# iorx62n register map
Registers are 8-bit, access not given, no defined reset value unless marked. A register's access mark holds for its fields unless they carry their own. Addresses are absolute; registers are grouped by the start of their names; [hi:lo] are bit positions; {n}, {i} and the like mark numbered series; 'fields as' and 'values as' point back to an identical list.

## SFR (part 3 of 3)
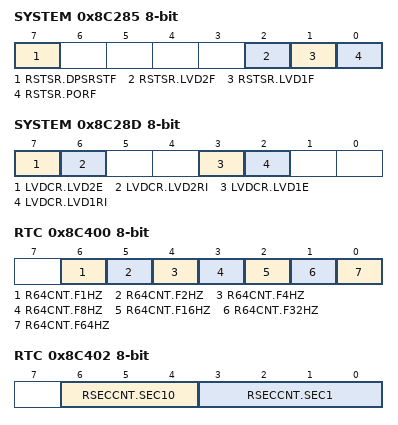
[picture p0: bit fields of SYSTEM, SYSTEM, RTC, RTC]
0x8C285 SYSTEM
  [7] RSTSR.DPSRSTF, [2] RSTSR.LVD2F, [1] RSTSR.LVD1F, [0] RSTSR.PORF
0x8C289 FLASH
  [1:0] FWEPROR.FLWE
0x8C28A SYSTEM
  [0] SUBOSCCR.SUBSTOP
0x8C28D SYSTEM
  [7] LVDCR.LVD2E, [6] LVDCR.LVD2RI, [3] LVDCR.LVD1E, [2] LVDCR.LVD1RI
0x8C400 RTC
  [6] R64CNT.F1HZ, [5] R64CNT.F2HZ, [4] R64CNT.F4HZ, [3] R64CNT.F8HZ, [2] R64CNT.F16HZ, [1] R64CNT.F32HZ, [0] R64CNT.F64HZ
0x8C402 RTC
  [6:4] RSECCNT.SEC10, [3:0] RSECCNT.SEC1
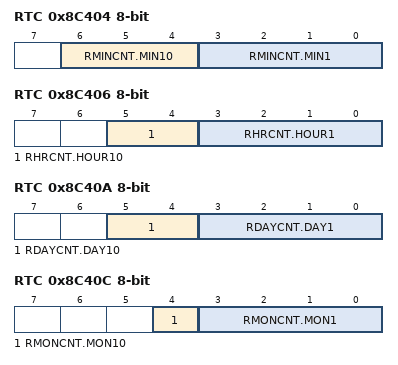
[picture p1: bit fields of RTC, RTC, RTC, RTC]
0x8C404 RTC
  [6:4] RMINCNT.MIN10, [3:0] RMINCNT.MIN1
0x8C406 RTC
  [5:4] RHRCNT.HOUR10, [3:0] RHRCNT.HOUR1
0x8C408 RTC
  [2:0] RWKCNT.DAY
0x8C40A RTC
  [5:4] RDAYCNT.DAY10, [3:0] RDAYCNT.DAY1
0x8C40C RTC
  [4] RMONCNT.MON10, [3:0] RMONCNT.MON1
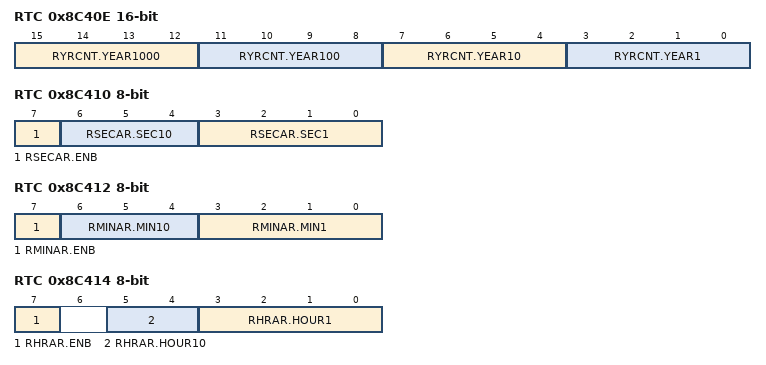
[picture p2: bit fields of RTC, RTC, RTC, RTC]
0x8C40E RTC 16-bit
  [15:12] RYRCNT.YEAR1000, [11:8] RYRCNT.YEAR100, [7:4] RYRCNT.YEAR10, [3:0] RYRCNT.YEAR1
0x8C410 RTC
  [7] RSECAR.ENB, [6:4] RSECAR.SEC10, [3:0] RSECAR.SEC1
0x8C412 RTC
  [7] RMINAR.ENB, [6:4] RMINAR.MIN10, [3:0] RMINAR.MIN1
0x8C414 RTC
  [7] RHRAR.ENB, [5:4] RHRAR.HOUR10, [3:0] RHRAR.HOUR1
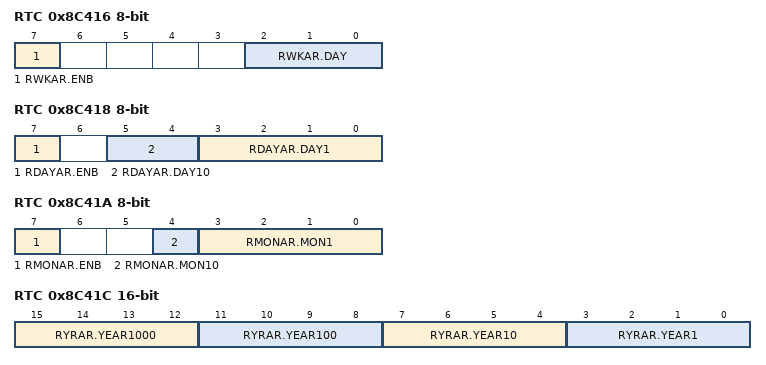
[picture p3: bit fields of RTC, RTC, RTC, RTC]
0x8C416 RTC
  [7] RWKAR.ENB, [2:0] RWKAR.DAY
0x8C418 RTC
  [7] RDAYAR.ENB, [5:4] RDAYAR.DAY10, [3:0] RDAYAR.DAY1
0x8C41A RTC
  [7] RMONAR.ENB, [4] RMONAR.MON10, [3:0] RMONAR.MON1
0x8C41C RTC 16-bit
  [15:12] RYRAR.YEAR1000, [11:8] RYRAR.YEAR100, [7:4] RYRAR.YEAR10, [3:0] RYRAR.YEAR1
0x8C41E RTC
  [7] RYRAREN.ENB
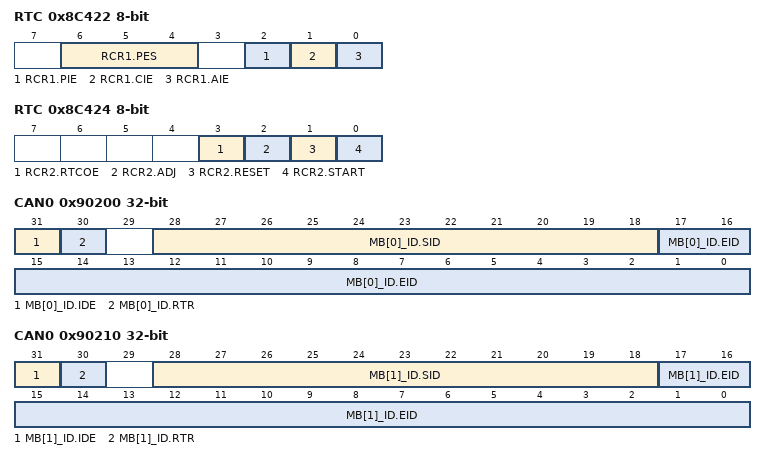
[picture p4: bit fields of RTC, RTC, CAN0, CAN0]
0x8C422 RTC
  [6:4] RCR1.PES, [2] RCR1.PIE, [1] RCR1.CIE, [0] RCR1.AIE
0x8C424 RTC
  [3] RCR2.RTCOE, [2] RCR2.ADJ, [1] RCR2.RESET, [0] RCR2.START
0x90200 CAN0 32-bit
  [31] MB[0]_ID.IDE, [30] MB[0]_ID.RTR, [28:18] MB[0]_ID.SID, [17:0] MB[0]_ID.EID
0x90204 CAN0 16-bit
  [3:0] MB[0]_DLC.DLC
0x90210 CAN0 32-bit
  [31] MB[1]_ID.IDE, [30] MB[1]_ID.RTR, [28:18] MB[1]_ID.SID, [17:0] MB[1]_ID.EID
0x90214 CAN0 16-bit
  [3:0] MB[1]_DLC.DLC
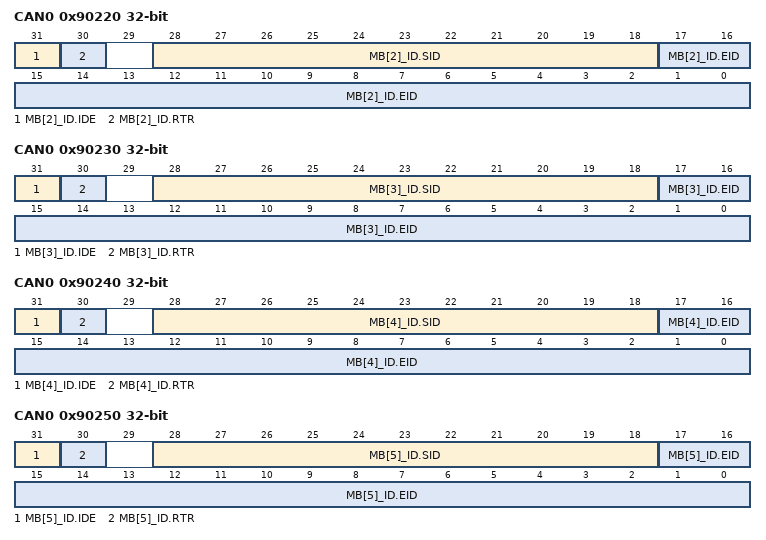
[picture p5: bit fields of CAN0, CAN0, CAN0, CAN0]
0x90220 CAN0 32-bit
  [31] MB[2]_ID.IDE, [30] MB[2]_ID.RTR, [28:18] MB[2]_ID.SID, [17:0] MB[2]_ID.EID
0x90224 CAN0 16-bit
  [3:0] MB[2]_DLC.DLC
0x90230 CAN0 32-bit
  [31] MB[3]_ID.IDE, [30] MB[3]_ID.RTR, [28:18] MB[3]_ID.SID, [17:0] MB[3]_ID.EID
0x90234 CAN0 16-bit
  [3:0] MB[3]_DLC.DLC
0x90240 CAN0 32-bit
  [31] MB[4]_ID.IDE, [30] MB[4]_ID.RTR, [28:18] MB[4]_ID.SID, [17:0] MB[4]_ID.EID
0x90244 CAN0 16-bit
  [3:0] MB[4]_DLC.DLC
0x90250 CAN0 32-bit
  [31] MB[5]_ID.IDE, [30] MB[5]_ID.RTR, [28:18] MB[5]_ID.SID, [17:0] MB[5]_ID.EID
0x90254 CAN0 16-bit
  [3:0] MB[5]_DLC.DLC
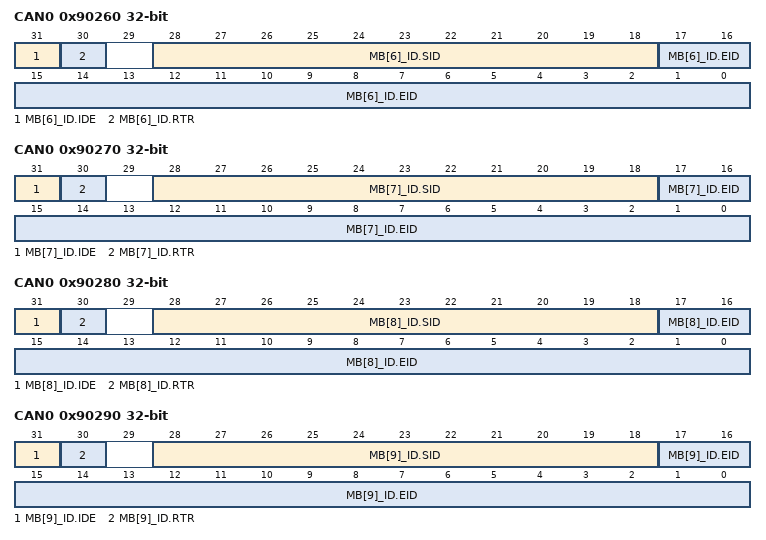
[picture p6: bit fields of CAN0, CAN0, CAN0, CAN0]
0x90260 CAN0 32-bit
  [31] MB[6]_ID.IDE, [30] MB[6]_ID.RTR, [28:18] MB[6]_ID.SID, [17:0] MB[6]_ID.EID
0x90264 CAN0 16-bit
  [3:0] MB[6]_DLC.DLC
0x90270 CAN0 32-bit
  [31] MB[7]_ID.IDE, [30] MB[7]_ID.RTR, [28:18] MB[7]_ID.SID, [17:0] MB[7]_ID.EID
0x90274 CAN0 16-bit
  [3:0] MB[7]_DLC.DLC
0x90280 CAN0 32-bit
  [31] MB[8]_ID.IDE, [30] MB[8]_ID.RTR, [28:18] MB[8]_ID.SID, [17:0] MB[8]_ID.EID
0x90284 CAN0 16-bit
  [3:0] MB[8]_DLC.DLC
0x90290 CAN0 32-bit
  [31] MB[9]_ID.IDE, [30] MB[9]_ID.RTR, [28:18] MB[9]_ID.SID, [17:0] MB[9]_ID.EID
0x90294 CAN0 16-bit
  [3:0] MB[9]_DLC.DLC
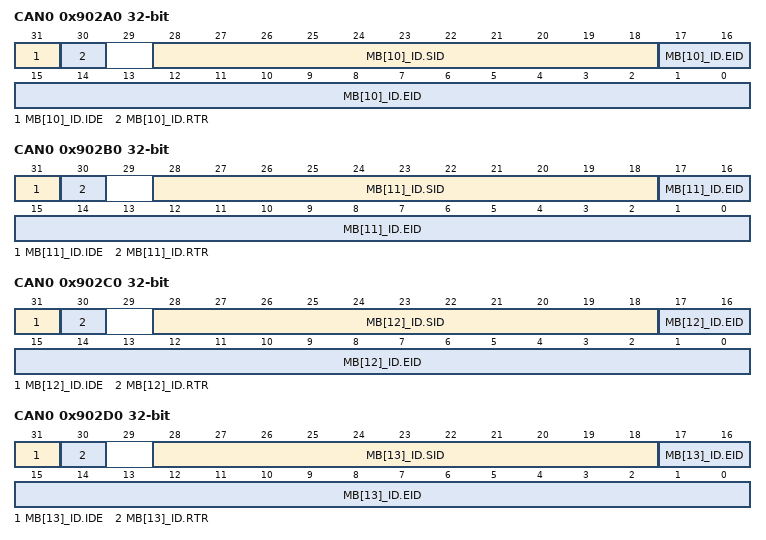
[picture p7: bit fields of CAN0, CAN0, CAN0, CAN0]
0x902A0 CAN0 32-bit
  [31] MB[10]_ID.IDE, [30] MB[10]_ID.RTR, [28:18] MB[10]_ID.SID, [17:0] MB[10]_ID.EID
0x902A4 CAN0 16-bit
  [3:0] MB[10]_DLC.DLC
0x902B0 CAN0 32-bit
  [31] MB[11]_ID.IDE, [30] MB[11]_ID.RTR, [28:18] MB[11]_ID.SID, [17:0] MB[11]_ID.EID
0x902B4 CAN0 16-bit
  [3:0] MB[11]_DLC.DLC
0x902C0 CAN0 32-bit
  [31] MB[12]_ID.IDE, [30] MB[12]_ID.RTR, [28:18] MB[12]_ID.SID, [17:0] MB[12]_ID.EID
0x902C4 CAN0 16-bit
  [3:0] MB[12]_DLC.DLC
0x902D0 CAN0 32-bit
  [31] MB[13]_ID.IDE, [30] MB[13]_ID.RTR, [28:18] MB[13]_ID.SID, [17:0] MB[13]_ID.EID
0x902D4 CAN0 16-bit
  [3:0] MB[13]_DLC.DLC
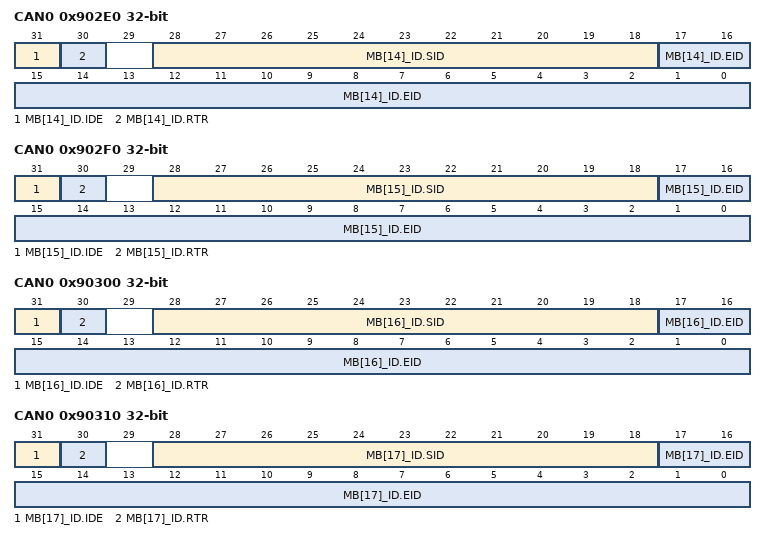
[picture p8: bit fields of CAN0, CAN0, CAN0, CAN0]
0x902E0 CAN0 32-bit
  [31] MB[14]_ID.IDE, [30] MB[14]_ID.RTR, [28:18] MB[14]_ID.SID, [17:0] MB[14]_ID.EID
0x902E4 CAN0 16-bit
  [3:0] MB[14]_DLC.DLC
0x902F0 CAN0 32-bit
  [31] MB[15]_ID.IDE, [30] MB[15]_ID.RTR, [28:18] MB[15]_ID.SID, [17:0] MB[15]_ID.EID
0x902F4 CAN0 16-bit
  [3:0] MB[15]_DLC.DLC
0x90300 CAN0 32-bit
  [31] MB[16]_ID.IDE, [30] MB[16]_ID.RTR, [28:18] MB[16]_ID.SID, [17:0] MB[16]_ID.EID
0x90304 CAN0 16-bit
  [3:0] MB[16]_DLC.DLC
0x90310 CAN0 32-bit
  [31] MB[17]_ID.IDE, [30] MB[17]_ID.RTR, [28:18] MB[17]_ID.SID, [17:0] MB[17]_ID.EID
0x90314 CAN0 16-bit
  [3:0] MB[17]_DLC.DLC
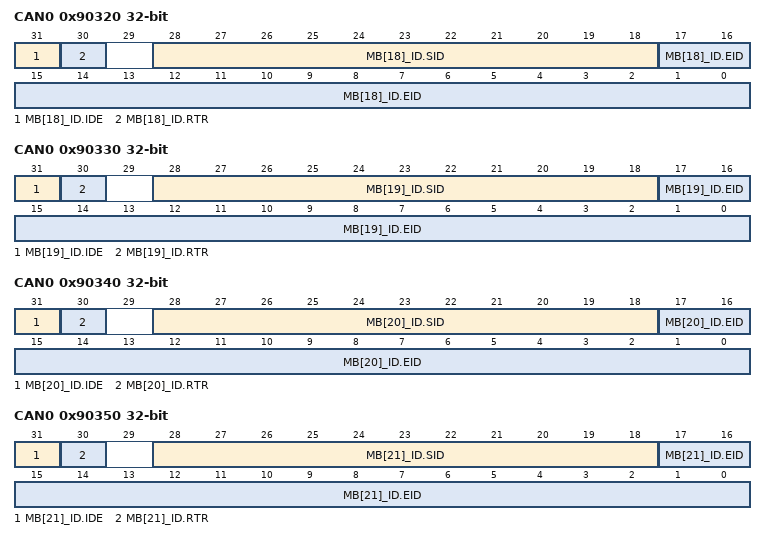
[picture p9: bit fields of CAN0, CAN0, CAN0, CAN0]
0x90320 CAN0 32-bit
  [31] MB[18]_ID.IDE, [30] MB[18]_ID.RTR, [28:18] MB[18]_ID.SID, [17:0] MB[18]_ID.EID
0x90324 CAN0 16-bit
  [3:0] MB[18]_DLC.DLC
0x90330 CAN0 32-bit
  [31] MB[19]_ID.IDE, [30] MB[19]_ID.RTR, [28:18] MB[19]_ID.SID, [17:0] MB[19]_ID.EID
0x90334 CAN0 16-bit
  [3:0] MB[19]_DLC.DLC
0x90340 CAN0 32-bit
  [31] MB[20]_ID.IDE, [30] MB[20]_ID.RTR, [28:18] MB[20]_ID.SID, [17:0] MB[20]_ID.EID
0x90344 CAN0 16-bit
  [3:0] MB[20]_DLC.DLC
0x90350 CAN0 32-bit
  [31] MB[21]_ID.IDE, [30] MB[21]_ID.RTR, [28:18] MB[21]_ID.SID, [17:0] MB[21]_ID.EID
0x90354 CAN0 16-bit
  [3:0] MB[21]_DLC.DLC
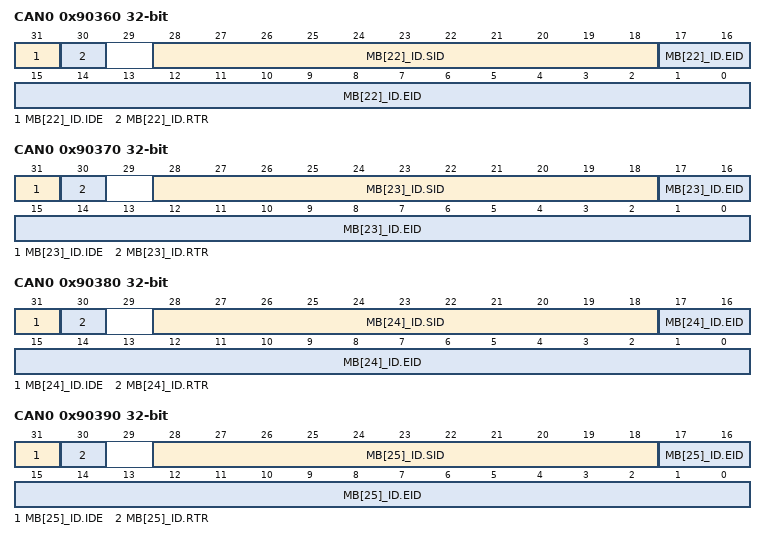
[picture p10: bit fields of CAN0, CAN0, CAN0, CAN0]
0x90360 CAN0 32-bit
  [31] MB[22]_ID.IDE, [30] MB[22]_ID.RTR, [28:18] MB[22]_ID.SID, [17:0] MB[22]_ID.EID
0x90364 CAN0 16-bit
  [3:0] MB[22]_DLC.DLC
0x90370 CAN0 32-bit
  [31] MB[23]_ID.IDE, [30] MB[23]_ID.RTR, [28:18] MB[23]_ID.SID, [17:0] MB[23]_ID.EID
0x90374 CAN0 16-bit
  [3:0] MB[23]_DLC.DLC
0x90380 CAN0 32-bit
  [31] MB[24]_ID.IDE, [30] MB[24]_ID.RTR, [28:18] MB[24]_ID.SID, [17:0] MB[24]_ID.EID
0x90384 CAN0 16-bit
  [3:0] MB[24]_DLC.DLC
0x90390 CAN0 32-bit
  [31] MB[25]_ID.IDE, [30] MB[25]_ID.RTR, [28:18] MB[25]_ID.SID, [17:0] MB[25]_ID.EID
0x90394 CAN0 16-bit
  [3:0] MB[25]_DLC.DLC
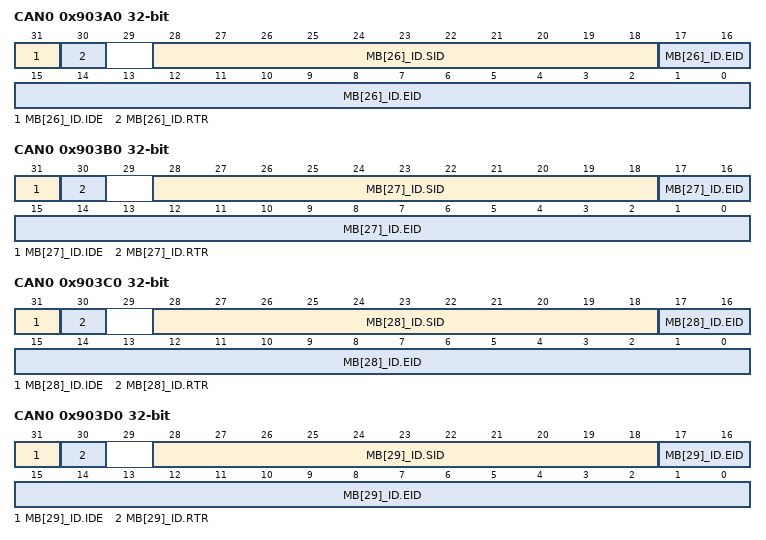
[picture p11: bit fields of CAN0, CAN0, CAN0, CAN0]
0x903A0 CAN0 32-bit
  [31] MB[26]_ID.IDE, [30] MB[26]_ID.RTR, [28:18] MB[26]_ID.SID, [17:0] MB[26]_ID.EID
0x903A4 CAN0 16-bit
  [3:0] MB[26]_DLC.DLC
0x903B0 CAN0 32-bit
  [31] MB[27]_ID.IDE, [30] MB[27]_ID.RTR, [28:18] MB[27]_ID.SID, [17:0] MB[27]_ID.EID
0x903B4 CAN0 16-bit
  [3:0] MB[27]_DLC.DLC
0x903C0 CAN0 32-bit
  [31] MB[28]_ID.IDE, [30] MB[28]_ID.RTR, [28:18] MB[28]_ID.SID, [17:0] MB[28]_ID.EID
0x903C4 CAN0 16-bit
  [3:0] MB[28]_DLC.DLC
0x903D0 CAN0 32-bit
  [31] MB[29]_ID.IDE, [30] MB[29]_ID.RTR, [28:18] MB[29]_ID.SID, [17:0] MB[29]_ID.EID
0x903D4 CAN0 16-bit
  [3:0] MB[29]_DLC.DLC
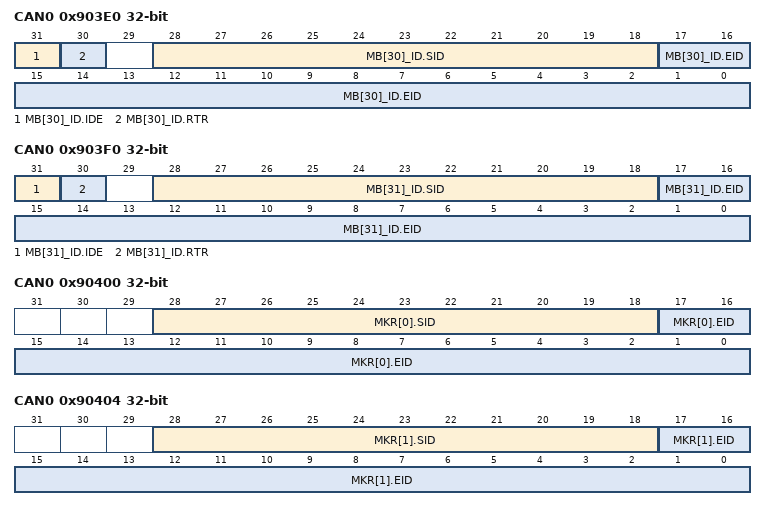
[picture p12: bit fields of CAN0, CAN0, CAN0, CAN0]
0x903E0 CAN0 32-bit
  [31] MB[30]_ID.IDE, [30] MB[30]_ID.RTR, [28:18] MB[30]_ID.SID, [17:0] MB[30]_ID.EID
0x903E4 CAN0 16-bit
  [3:0] MB[30]_DLC.DLC
0x903F0 CAN0 32-bit
  [31] MB[31]_ID.IDE, [30] MB[31]_ID.RTR, [28:18] MB[31]_ID.SID, [17:0] MB[31]_ID.EID
0x903F4 CAN0 16-bit
  [3:0] MB[31]_DLC.DLC
0x90400 CAN0 32-bit
  [28:18] MKR[0].SID, [17:0] MKR[0].EID
0x90404 CAN0 32-bit
  [28:18] MKR[1].SID, [17:0] MKR[1].EID
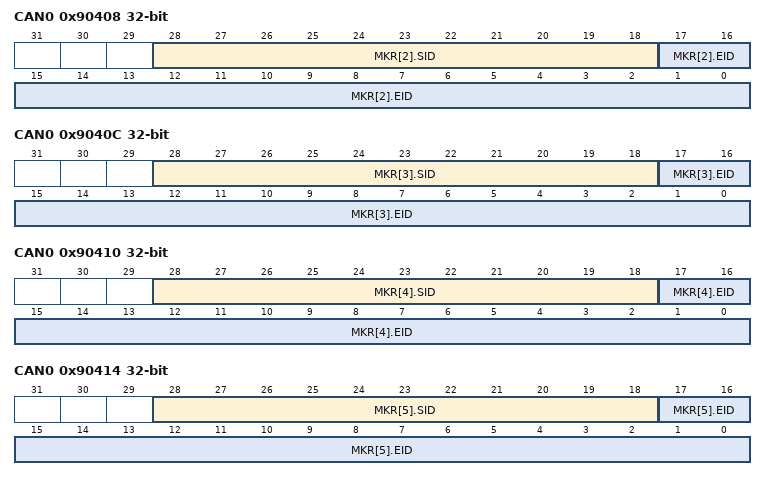
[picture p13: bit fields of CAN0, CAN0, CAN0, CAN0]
0x90408 CAN0 32-bit
  [28:18] MKR[2].SID, [17:0] MKR[2].EID
0x9040C CAN0 32-bit
  [28:18] MKR[3].SID, [17:0] MKR[3].EID
0x90410 CAN0 32-bit
  [28:18] MKR[4].SID, [17:0] MKR[4].EID
0x90414 CAN0 32-bit
  [28:18] MKR[5].SID, [17:0] MKR[5].EID
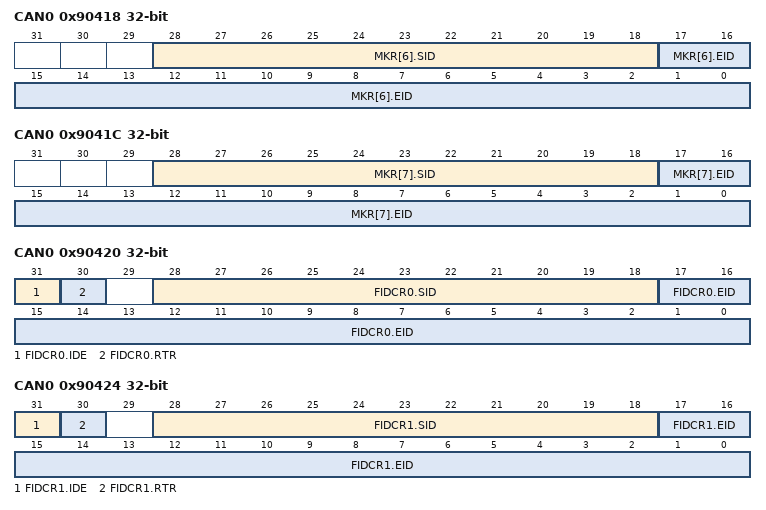
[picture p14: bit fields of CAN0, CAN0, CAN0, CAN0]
0x90418 CAN0 32-bit
  [28:18] MKR[6].SID, [17:0] MKR[6].EID
0x9041C CAN0 32-bit
  [28:18] MKR[7].SID, [17:0] MKR[7].EID
0x90420 CAN0 32-bit
  [31] FIDCR0.IDE, [30] FIDCR0.RTR, [28:18] FIDCR0.SID, [17:0] FIDCR0.EID
0x90424 CAN0 32-bit
  [31] FIDCR1.IDE, [30] FIDCR1.RTR, [28:18] FIDCR1.SID, [17:0] FIDCR1.EID
0x90820 CAN0
  [7] MCTL[0]_TX.TRMREQ, [7] MCTL[0]_RX.TRMREQ, [6] MCTL[0]_TX.RECREQ, [6] MCTL[0]_RX.RECREQ, [4] MCTL[0]_TX.ONESHOT, [4] MCTL[0]_RX.ONESHOT, [2] MCTL[0]_TX.TRMABT, [2] MCTL[0]_RX.MSGLOST, [1] MCTL[0]_TX.TRMACTIVE, [1] MCTL[0]_RX.INVALDATA, [0] MCTL[0]_TX.SENTDATA, [0] MCTL[0]_RX.NEWDATA
0x90821 CAN0
  [7] MCTL[1]_TX.TRMREQ, [7] MCTL[1]_RX.TRMREQ, [6] MCTL[1]_TX.RECREQ, [6] MCTL[1]_RX.RECREQ, [4] MCTL[1]_TX.ONESHOT, [4] MCTL[1]_RX.ONESHOT, [2] MCTL[1]_TX.TRMABT, [2] MCTL[1]_RX.MSGLOST, [1] MCTL[1]_TX.TRMACTIVE, [1] MCTL[1]_RX.INVALDATA, [0] MCTL[1]_TX.SENTDATA, [0] MCTL[1]_RX.NEWDATA
0x90822 CAN0
  [7] MCTL[2]_TX.TRMREQ, [7] MCTL[2]_RX.TRMREQ, [6] MCTL[2]_TX.RECREQ, [6] MCTL[2]_RX.RECREQ, [4] MCTL[2]_TX.ONESHOT, [4] MCTL[2]_RX.ONESHOT, [2] MCTL[2]_TX.TRMABT, [2] MCTL[2]_RX.MSGLOST, [1] MCTL[2]_TX.TRMACTIVE, [1] MCTL[2]_RX.INVALDATA, [0] MCTL[2]_TX.SENTDATA, [0] MCTL[2]_RX.NEWDATA
0x90823 CAN0
  [7] MCTL[3]_TX.TRMREQ, [7] MCTL[3]_RX.TRMREQ, [6] MCTL[3]_TX.RECREQ, [6] MCTL[3]_RX.RECREQ, [4] MCTL[3]_TX.ONESHOT, [4] MCTL[3]_RX.ONESHOT, [2] MCTL[3]_TX.TRMABT, [2] MCTL[3]_RX.MSGLOST, [1] MCTL[3]_TX.TRMACTIVE, [1] MCTL[3]_RX.INVALDATA, [0] MCTL[3]_TX.SENTDATA, [0] MCTL[3]_RX.NEWDATA
0x90824 CAN0
  [7] MCTL[4]_TX.TRMREQ, [7] MCTL[4]_RX.TRMREQ, [6] MCTL[4]_TX.RECREQ, [6] MCTL[4]_RX.RECREQ, [4] MCTL[4]_TX.ONESHOT, [4] MCTL[4]_RX.ONESHOT, [2] MCTL[4]_TX.TRMABT, [2] MCTL[4]_RX.MSGLOST, [1] MCTL[4]_TX.TRMACTIVE, [1] MCTL[4]_RX.INVALDATA, [0] MCTL[4]_TX.SENTDATA, [0] MCTL[4]_RX.NEWDATA
0x90825 CAN0
  [7] MCTL[5]_TX.TRMREQ, [7] MCTL[5]_RX.TRMREQ, [6] MCTL[5]_TX.RECREQ, [6] MCTL[5]_RX.RECREQ, [4] MCTL[5]_TX.ONESHOT, [4] MCTL[5]_RX.ONESHOT, [2] MCTL[5]_TX.TRMABT, [2] MCTL[5]_RX.MSGLOST, [1] MCTL[5]_TX.TRMACTIVE, [1] MCTL[5]_RX.INVALDATA, [0] MCTL[5]_TX.SENTDATA, [0] MCTL[5]_RX.NEWDATA
0x90826 CAN0
  [7] MCTL[6]_TX.TRMREQ, [7] MCTL[6]_RX.TRMREQ, [6] MCTL[6]_TX.RECREQ, [6] MCTL[6]_RX.RECREQ, [4] MCTL[6]_TX.ONESHOT, [4] MCTL[6]_RX.ONESHOT, [2] MCTL[6]_TX.TRMABT, [2] MCTL[6]_RX.MSGLOST, [1] MCTL[6]_TX.TRMACTIVE, [1] MCTL[6]_RX.INVALDATA, [0] MCTL[6]_TX.SENTDATA, [0] MCTL[6]_RX.NEWDATA
0x90827 CAN0
  [7] MCTL[7]_TX.TRMREQ, [7] MCTL[7]_RX.TRMREQ, [6] MCTL[7]_TX.RECREQ, [6] MCTL[7]_RX.RECREQ, [4] MCTL[7]_TX.ONESHOT, [4] MCTL[7]_RX.ONESHOT, [2] MCTL[7]_TX.TRMABT, [2] MCTL[7]_RX.MSGLOST, [1] MCTL[7]_TX.TRMACTIVE, [1] MCTL[7]_RX.INVALDATA, [0] MCTL[7]_TX.SENTDATA, [0] MCTL[7]_RX.NEWDATA
0x90828 CAN0
  [7] MCTL[8]_TX.TRMREQ, [7] MCTL[8]_RX.TRMREQ, [6] MCTL[8]_TX.RECREQ, [6] MCTL[8]_RX.RECREQ, [4] MCTL[8]_TX.ONESHOT, [4] MCTL[8]_RX.ONESHOT, [2] MCTL[8]_TX.TRMABT, [2] MCTL[8]_RX.MSGLOST, [1] MCTL[8]_TX.TRMACTIVE, [1] MCTL[8]_RX.INVALDATA, [0] MCTL[8]_TX.SENTDATA, [0] MCTL[8]_RX.NEWDATA
0x90829 CAN0
  [7] MCTL[9]_TX.TRMREQ, [7] MCTL[9]_RX.TRMREQ, [6] MCTL[9]_TX.RECREQ, [6] MCTL[9]_RX.RECREQ, [4] MCTL[9]_TX.ONESHOT, [4] MCTL[9]_RX.ONESHOT, [2] MCTL[9]_TX.TRMABT, [2] MCTL[9]_RX.MSGLOST, [1] MCTL[9]_TX.TRMACTIVE, [1] MCTL[9]_RX.INVALDATA, [0] MCTL[9]_TX.SENTDATA, [0] MCTL[9]_RX.NEWDATA
0x9082A CAN0
  [7] MCTL[10]_TX.TRMREQ, [7] MCTL[10]_RX.TRMREQ, [6] MCTL[10]_TX.RECREQ, [6] MCTL[10]_RX.RECREQ, [4] MCTL[10]_TX.ONESHOT, [4] MCTL[10]_RX.ONESHOT, [2] MCTL[10]_TX.TRMABT, [2] MCTL[10]_RX.MSGLOST, [1] MCTL[10]_TX.TRMACTIVE, [1] MCTL[10]_RX.INVALDATA, [0] MCTL[10]_TX.SENTDATA, [0] MCTL[10]_RX.NEWDATA
0x9082B CAN0
  [7] MCTL[11]_TX.TRMREQ, [7] MCTL[11]_RX.TRMREQ, [6] MCTL[11]_TX.RECREQ, [6] MCTL[11]_RX.RECREQ, [4] MCTL[11]_TX.ONESHOT, [4] MCTL[11]_RX.ONESHOT, [2] MCTL[11]_TX.TRMABT, [2] MCTL[11]_RX.MSGLOST, [1] MCTL[11]_TX.TRMACTIVE, [1] MCTL[11]_RX.INVALDATA, [0] MCTL[11]_TX.SENTDATA, [0] MCTL[11]_RX.NEWDATA
0x9082C CAN0
  [7] MCTL[12]_TX.TRMREQ, [7] MCTL[12]_RX.TRMREQ, [6] MCTL[12]_TX.RECREQ, [6] MCTL[12]_RX.RECREQ, [4] MCTL[12]_TX.ONESHOT, [4] MCTL[12]_RX.ONESHOT, [2] MCTL[12]_TX.TRMABT, [2] MCTL[12]_RX.MSGLOST, [1] MCTL[12]_TX.TRMACTIVE, [1] MCTL[12]_RX.INVALDATA, [0] MCTL[12]_TX.SENTDATA, [0] MCTL[12]_RX.NEWDATA
0x9082D CAN0
  [7] MCTL[13]_TX.TRMREQ, [7] MCTL[13]_RX.TRMREQ, [6] MCTL[13]_TX.RECREQ, [6] MCTL[13]_RX.RECREQ, [4] MCTL[13]_TX.ONESHOT, [4] MCTL[13]_RX.ONESHOT, [2] MCTL[13]_TX.TRMABT, [2] MCTL[13]_RX.MSGLOST, [1] MCTL[13]_TX.TRMACTIVE, [1] MCTL[13]_RX.INVALDATA, [0] MCTL[13]_TX.SENTDATA, [0] MCTL[13]_RX.NEWDATA
0x9082E CAN0
  [7] MCTL[14]_TX.TRMREQ, [7] MCTL[14]_RX.TRMREQ, [6] MCTL[14]_TX.RECREQ, [6] MCTL[14]_RX.RECREQ, [4] MCTL[14]_TX.ONESHOT, [4] MCTL[14]_RX.ONESHOT, [2] MCTL[14]_TX.TRMABT, [2] MCTL[14]_RX.MSGLOST, [1] MCTL[14]_TX.TRMACTIVE, [1] MCTL[14]_RX.INVALDATA, [0] MCTL[14]_TX.SENTDATA, [0] MCTL[14]_RX.NEWDATA
0x9082F CAN0
  [7] MCTL[15]_TX.TRMREQ, [7] MCTL[15]_RX.TRMREQ, [6] MCTL[15]_TX.RECREQ, [6] MCTL[15]_RX.RECREQ, [4] MCTL[15]_TX.ONESHOT, [4] MCTL[15]_RX.ONESHOT, [2] MCTL[15]_TX.TRMABT, [2] MCTL[15]_RX.MSGLOST, [1] MCTL[15]_TX.TRMACTIVE, [1] MCTL[15]_RX.INVALDATA, [0] MCTL[15]_TX.SENTDATA, [0] MCTL[15]_RX.NEWDATA
0x90830 CAN0
  [7] MCTL[16]_TX.TRMREQ, [7] MCTL[16]_RX.TRMREQ, [6] MCTL[16]_TX.RECREQ, [6] MCTL[16]_RX.RECREQ, [4] MCTL[16]_TX.ONESHOT, [4] MCTL[16]_RX.ONESHOT, [2] MCTL[16]_TX.TRMABT, [2] MCTL[16]_RX.MSGLOST, [1] MCTL[16]_TX.TRMACTIVE, [1] MCTL[16]_RX.INVALDATA, [0] MCTL[16]_TX.SENTDATA, [0] MCTL[16]_RX.NEWDATA
0x90831 CAN0
  [7] MCTL[17]_TX.TRMREQ, [7] MCTL[17]_RX.TRMREQ, [6] MCTL[17]_TX.RECREQ, [6] MCTL[17]_RX.RECREQ, [4] MCTL[17]_TX.ONESHOT, [4] MCTL[17]_RX.ONESHOT, [2] MCTL[17]_TX.TRMABT, [2] MCTL[17]_RX.MSGLOST, [1] MCTL[17]_TX.TRMACTIVE, [1] MCTL[17]_RX.INVALDATA, [0] MCTL[17]_TX.SENTDATA, [0] MCTL[17]_RX.NEWDATA
0x90832 CAN0
  [7] MCTL[18]_TX.TRMREQ, [7] MCTL[18]_RX.TRMREQ, [6] MCTL[18]_TX.RECREQ, [6] MCTL[18]_RX.RECREQ, [4] MCTL[18]_TX.ONESHOT, [4] MCTL[18]_RX.ONESHOT, [2] MCTL[18]_TX.TRMABT, [2] MCTL[18]_RX.MSGLOST, [1] MCTL[18]_TX.TRMACTIVE, [1] MCTL[18]_RX.INVALDATA, [0] MCTL[18]_TX.SENTDATA, [0] MCTL[18]_RX.NEWDATA
0x90833 CAN0
  [7] MCTL[19]_TX.TRMREQ, [7] MCTL[19]_RX.TRMREQ, [6] MCTL[19]_TX.RECREQ, [6] MCTL[19]_RX.RECREQ, [4] MCTL[19]_TX.ONESHOT, [4] MCTL[19]_RX.ONESHOT, [2] MCTL[19]_TX.TRMABT, [2] MCTL[19]_RX.MSGLOST, [1] MCTL[19]_TX.TRMACTIVE, [1] MCTL[19]_RX.INVALDATA, [0] MCTL[19]_TX.SENTDATA, [0] MCTL[19]_RX.NEWDATA
0x90834 CAN0
  [7] MCTL[20]_TX.TRMREQ, [7] MCTL[20]_RX.TRMREQ, [6] MCTL[20]_TX.RECREQ, [6] MCTL[20]_RX.RECREQ, [4] MCTL[20]_TX.ONESHOT, [4] MCTL[20]_RX.ONESHOT, [2] MCTL[20]_TX.TRMABT, [2] MCTL[20]_RX.MSGLOST, [1] MCTL[20]_TX.TRMACTIVE, [1] MCTL[20]_RX.INVALDATA, [0] MCTL[20]_TX.SENTDATA, [0] MCTL[20]_RX.NEWDATA
0x90835 CAN0
  [7] MCTL[21]_TX.TRMREQ, [7] MCTL[21]_RX.TRMREQ, [6] MCTL[21]_TX.RECREQ, [6] MCTL[21]_RX.RECREQ, [4] MCTL[21]_TX.ONESHOT, [4] MCTL[21]_RX.ONESHOT, [2] MCTL[21]_TX.TRMABT, [2] MCTL[21]_RX.MSGLOST, [1] MCTL[21]_TX.TRMACTIVE, [1] MCTL[21]_RX.INVALDATA, [0] MCTL[21]_TX.SENTDATA, [0] MCTL[21]_RX.NEWDATA
0x90836 CAN0
  [7] MCTL[22]_TX.TRMREQ, [7] MCTL[22]_RX.TRMREQ, [6] MCTL[22]_TX.RECREQ, [6] MCTL[22]_RX.RECREQ, [4] MCTL[22]_TX.ONESHOT, [4] MCTL[22]_RX.ONESHOT, [2] MCTL[22]_TX.TRMABT, [2] MCTL[22]_RX.MSGLOST, [1] MCTL[22]_TX.TRMACTIVE, [1] MCTL[22]_RX.INVALDATA, [0] MCTL[22]_TX.SENTDATA, [0] MCTL[22]_RX.NEWDATA
0x90837 CAN0
  [7] MCTL[23]_TX.TRMREQ, [7] MCTL[23]_RX.TRMREQ, [6] MCTL[23]_TX.RECREQ, [6] MCTL[23]_RX.RECREQ, [4] MCTL[23]_TX.ONESHOT, [4] MCTL[23]_RX.ONESHOT, [2] MCTL[23]_TX.TRMABT, [2] MCTL[23]_RX.MSGLOST, [1] MCTL[23]_TX.TRMACTIVE, [1] MCTL[23]_RX.INVALDATA, [0] MCTL[23]_TX.SENTDATA, [0] MCTL[23]_RX.NEWDATA
0x90838 CAN0
  [7] MCTL[24]_TX.TRMREQ, [7] MCTL[24]_RX.TRMREQ, [6] MCTL[24]_TX.RECREQ, [6] MCTL[24]_RX.RECREQ, [4] MCTL[24]_TX.ONESHOT, [4] MCTL[24]_RX.ONESHOT, [2] MCTL[24]_TX.TRMABT, [2] MCTL[24]_RX.MSGLOST, [1] MCTL[24]_TX.TRMACTIVE, [1] MCTL[24]_RX.INVALDATA, [0] MCTL[24]_TX.SENTDATA, [0] MCTL[24]_RX.NEWDATA
0x90839 CAN0
  [7] MCTL[25]_TX.TRMREQ, [7] MCTL[25]_RX.TRMREQ, [6] MCTL[25]_TX.RECREQ, [6] MCTL[25]_RX.RECREQ, [4] MCTL[25]_TX.ONESHOT, [4] MCTL[25]_RX.ONESHOT, [2] MCTL[25]_TX.TRMABT, [2] MCTL[25]_RX.MSGLOST, [1] MCTL[25]_TX.TRMACTIVE, [1] MCTL[25]_RX.INVALDATA, [0] MCTL[25]_TX.SENTDATA, [0] MCTL[25]_RX.NEWDATA
0x9083A CAN0
  [7] MCTL[26]_TX.TRMREQ, [7] MCTL[26]_RX.TRMREQ, [6] MCTL[26]_TX.RECREQ, [6] MCTL[26]_RX.RECREQ, [4] MCTL[26]_TX.ONESHOT, [4] MCTL[26]_RX.ONESHOT, [2] MCTL[26]_TX.TRMABT, [2] MCTL[26]_RX.MSGLOST, [1] MCTL[26]_TX.TRMACTIVE, [1] MCTL[26]_RX.INVALDATA, [0] MCTL[26]_TX.SENTDATA, [0] MCTL[26]_RX.NEWDATA
0x9083B CAN0
  [7] MCTL[27]_TX.TRMREQ, [7] MCTL[27]_RX.TRMREQ, [6] MCTL[27]_TX.RECREQ, [6] MCTL[27]_RX.RECREQ, [4] MCTL[27]_TX.ONESHOT, [4] MCTL[27]_RX.ONESHOT, [2] MCTL[27]_TX.TRMABT, [2] MCTL[27]_RX.MSGLOST, [1] MCTL[27]_TX.TRMACTIVE, [1] MCTL[27]_RX.INVALDATA, [0] MCTL[27]_TX.SENTDATA, [0] MCTL[27]_RX.NEWDATA
0x9083C CAN0
  [7] MCTL[28]_TX.TRMREQ, [7] MCTL[28]_RX.TRMREQ, [6] MCTL[28]_TX.RECREQ, [6] MCTL[28]_RX.RECREQ, [4] MCTL[28]_TX.ONESHOT, [4] MCTL[28]_RX.ONESHOT, [2] MCTL[28]_TX.TRMABT, [2] MCTL[28]_RX.MSGLOST, [1] MCTL[28]_TX.TRMACTIVE, [1] MCTL[28]_RX.INVALDATA, [0] MCTL[28]_TX.SENTDATA, [0] MCTL[28]_RX.NEWDATA
0x9083D CAN0
  [7] MCTL[29]_TX.TRMREQ, [7] MCTL[29]_RX.TRMREQ, [6] MCTL[29]_TX.RECREQ, [6] MCTL[29]_RX.RECREQ, [4] MCTL[29]_TX.ONESHOT, [4] MCTL[29]_RX.ONESHOT, [2] MCTL[29]_TX.TRMABT, [2] MCTL[29]_RX.MSGLOST, [1] MCTL[29]_TX.TRMACTIVE, [1] MCTL[29]_RX.INVALDATA, [0] MCTL[29]_TX.SENTDATA, [0] MCTL[29]_RX.NEWDATA
0x9083E CAN0
  [7] MCTL[30]_TX.TRMREQ, [7] MCTL[30]_RX.TRMREQ, [6] MCTL[30]_TX.RECREQ, [6] MCTL[30]_RX.RECREQ, [4] MCTL[30]_TX.ONESHOT, [4] MCTL[30]_RX.ONESHOT, [2] MCTL[30]_TX.TRMABT, [2] MCTL[30]_RX.MSGLOST, [1] MCTL[30]_TX.TRMACTIVE, [1] MCTL[30]_RX.INVALDATA, [0] MCTL[30]_TX.SENTDATA, [0] MCTL[30]_RX.NEWDATA
0x9083F CAN0
  [7] MCTL[31]_TX.TRMREQ, [7] MCTL[31]_RX.TRMREQ, [6] MCTL[31]_TX.RECREQ, [6] MCTL[31]_RX.RECREQ, [4] MCTL[31]_TX.ONESHOT, [4] MCTL[31]_RX.ONESHOT, [2] MCTL[31]_TX.TRMABT, [2] MCTL[31]_RX.MSGLOST, [1] MCTL[31]_TX.TRMACTIVE, [1] MCTL[31]_RX.INVALDATA, [0] MCTL[31]_TX.SENTDATA, [0] MCTL[31]_RX.NEWDATA
0x90840 CAN0 16-bit
  [13] CTLR.RBOC, [12:11] CTLR.BOM, [10] CTLR.SLPM, [9:8] CTLR.CANM, [7:6] CTLR.TSPS, [5] CTLR.TSRC, [4] CTLR.TPM, [3] CTLR.MLM, [2:1] CTLR.IDFM, [0] CTLR.MBM
0x90842 CAN0 16-bit
  [14] STR.RECST, [13] STR.TRMST, [12] STR.BOST, [11] STR.EPST, [10] STR.SLPST, [9] STR.HLTST, [8] STR.RSTST, [7] STR.EST, [6] STR.TABST, [5] STR.FMLST, [4] STR.NMLST, [3] STR.TFST, [2] STR.RFST, [1] STR.SDST, [0] STR.NDST
0x90844 CAN0 32-bit
  [31:28] BCR.TSEG1, [25:16] BCR.BRP, [13:12] BCR.SJW, [10:8] BCR.TSEG2
0x90848 CAN0
  [7] RFCR.RFEST, [6] RFCR.RFWST, [5] RFCR.RFFST, [4] RFCR.RFMLF, [3:1] RFCR.RFUST, [0] RFCR.RFE
0x9084A CAN0
  [7] TFCR.TFEST, [6] TFCR.TFFST, [3:1] TFCR.TFUST, [0] TFCR.TFE
0x9084C CAN0
  [7] EIER.BLIE, [6] EIER.OLIE, [5] EIER.ORIE, [4] EIER.BORIE, [3] EIER.BOEIE, [2] EIER.EPIE, [1] EIER.EWIE, [0] EIER.BEIE
0x9084D CAN0
  [7] EIFR.BLIF, [6] EIFR.OLIF, [5] EIFR.ORIF, [4] EIFR.BORIF, [3] EIFR.BOEIF, [2] EIFR.EPIF, [1] EIFR.EWIF, [0] EIFR.BEIF
0x90850 CAN0
  [7] ECSR.EDPM, [6] ECSR.ADEF, [5] ECSR.BE0F, [4] ECSR.BE1F, [3] ECSR.CEF, [2] ECSR.AEF, [1] ECSR.FEF, [0] ECSR.SEF
0x90852 CAN0
  [7] MSSR.SEST, [4:0] MSSR.MBNST
0x90853 CAN0
  [1:0] MSMR.MBSM
0x90858 CAN0
  [2:1] TCR.TSTM, [0] TCR.TSTE
0xA0000 USB0 16-bit
  [10] SYSCFG.SCKE, [6] SYSCFG.DCFM, [5] SYSCFG.DRPD, [4] SYSCFG.DPRPU, [0] SYSCFG.USBE
0xA0004 USB0 16-bit
  [15:14] SYSSTS0.OVCMON, [6] SYSSTS0.HTACT, [2] SYSSTS0.IDMON, [1:0] SYSSTS0.LNST
0xA0008 USB0 16-bit
  [11] DVSTCTR0.HNPBTOA, [10] DVSTCTR0.EXICEN, [9] DVSTCTR0.VBUSEN, [8] DVSTCTR0.WKUP, [7] DVSTCTR0.RWUPE, [6] DVSTCTR0.USBRST, [5] DVSTCTR0.RESUME, [4] DVSTCTR0.UACT, [2:0] DVSTCTR0.RHST
0xA0014 USB0 16-bit
  [15:8] CFIFO.L, [7:0] CFIFO.H
0xA0018 USB0 16-bit
  [15:8] D0FIFO.L, [7:0] D0FIFO.H
0xA001C USB0 16-bit
  [15:8] D1FIFO.L, [7:0] D1FIFO.H
0xA0020 USB0 16-bit
  [15] CFIFOSEL.RCNT, [14] CFIFOSEL.REW, [10] CFIFOSEL.MBW, [8] CFIFOSEL.BIGEND, [5] CFIFOSEL.ISEL, [3:0] CFIFOSEL.CURPIPE
0xA0022 USB0 16-bit
  [15] CFIFOCTR.BVAL, [14] CFIFOCTR.BCLR, [13] CFIFOCTR.FRDY, [8:0] CFIFOCTR.DTLN
0xA0028 USB0 16-bit
  [15] D0FIFOSEL.RCNT, [14] D0FIFOSEL.REW, [13] D0FIFOSEL.DCLRM, [12] D0FIFOSEL.DREQE, [10] D0FIFOSEL.MBW, [8] D0FIFOSEL.BIGEND, [3:0] D0FIFOSEL.CURPIPE
0xA002A USB0 16-bit
  [15] D0FIFOCTR.BVAL, [14] D0FIFOCTR.BCLR, [13] D0FIFOCTR.FRDY, [8:0] D0FIFOCTR.DTLN
0xA002C USB0 16-bit
  [15] D1FIFOSEL.RCNT, [14] D1FIFOSEL.REW, [13] D1FIFOSEL.DCLRM, [12] D1FIFOSEL.DREQE, [10] D1FIFOSEL.MBW, [8] D1FIFOSEL.BIGEND, [3:0] D1FIFOSEL.CURPIPE
0xA002E USB0 16-bit
  [15] D1FIFOCTR.BVAL, [14] D1FIFOCTR.BCLR, [13] D1FIFOCTR.FRDY, [8:0] D1FIFOCTR.DTLN
0xA0030 USB0 16-bit
  [15] INTENB0.VBSE, [14] INTENB0.RSME, [13] INTENB0.SOFE, [12] INTENB0.DVSE, [11] INTENB0.CTRE, [10] INTENB0.BEMPE, [9] INTENB0.NRDYE, [8] INTENB0.BRDYE
0xA0032 USB0 16-bit
  [15] INTENB1.OVRCRE, [14] INTENB1.BCHGE, [12] INTENB1.DTCHE, [11] INTENB1.ATTCHE, [6] INTENB1.EOFERRE, [5] INTENB1.SIGNE, [4] INTENB1.SACKE
0xA0036 USB0 16-bit
  [n] BRDYENB.PIPE{n}BRDYE (n=0..9)
0xA0038 USB0 16-bit
  [n] NRDYENB.PIPE{n}NRDYE (n=0..9)
0xA003A USB0 16-bit
  [n] BEMPENB.PIPE{n}BEMPE (n=0..9)
0xA003C USB0 16-bit
  [8] SOFCFG.TRNENSEL, [6] SOFCFG.BRDYM, [4] SOFCFG.EDGESTS
0xA0040 USB0 16-bit
  [15] INTSTS0.VBINT, [14] INTSTS0.RESM, [13] INTSTS0.SOFR, [12] INTSTS0.DVST, [11] INTSTS0.CTRT, [10] INTSTS0.BEMP, [9] INTSTS0.NRDY, [8] INTSTS0.BRDY, [7] INTSTS0.VBSTS, [6:4] INTSTS0.DVSQ, [3] INTSTS0.VALID, [2:0] INTSTS0.CTSQ
0xA0042 USB0 16-bit
  [15] INTSTS1.OVRCR, [14] INTSTS1.BCHG, [12] INTSTS1.DTCH, [11] INTSTS1.ATTCH, [6] INTSTS1.EOFERR, [5] INTSTS1.SIGN, [4] INTSTS1.SACK
0xA0046 USB0 16-bit
  [n] BRDYSTS.PIPE{n}BRDY (n=0..9)
0xA0048 USB0 16-bit
  [n] NRDYSTS.PIPE{n}NRDY (n=0..9)
0xA004A USB0 16-bit
  [n] BEMPSTS.PIPE{n}BEMP (n=0..9)
0xA004C USB0 16-bit
  [15] FRMNUM.OVRN, [14] FRMNUM.CRCE, [10:0] FRMNUM.FRNM
0xA004E USB0 16-bit
  [15] DVCHGR.DVCHG
0xA0050 USB0 16-bit
  [11:8] USBADDR.STSRECOV, [6:0] USBADDR.USBADDR
0xA0054 USB0 16-bit
  [15:8] USBREQ.BREQUEST, [7:0] USBREQ.BMREQUESTTYPE
0xA005C USB0 16-bit
  [7] DCPCFG.SHTNAK, [4] DCPCFG.DIR
0xA005E USB0 16-bit
  [15:12] DCPMAXP.DEVSEL, [6:0] DCPMAXP.MXPS
0xA0060 USB0 16-bit
  [15] DCPCTR.BSTS, [14] DCPCTR.SUREQ, [11] DCPCTR.SUREQCLR, [8] DCPCTR.SQCLR, [7] DCPCTR.SQSET, [6] DCPCTR.SQMON, [5] DCPCTR.PBUSY, [2] DCPCTR.CCPL, [1:0] DCPCTR.PID
0xA0064 USB0 16-bit
  [3:0] PIPESEL.PIPESEL
0xA0068 USB0 16-bit
  [15:14] PIPECFG.TYPE, [10] PIPECFG.BFRE, [9] PIPECFG.DBLB, [7] PIPECFG.SHTNAK, [4] PIPECFG.DIR, [3:0] PIPECFG.EPNUM
0xA006C USB0 16-bit
  [15:12] PIPEMAXP.DEVSEL, [8:0] PIPEMAXP.MXPS
0xA006E USB0 16-bit
  [12] PIPEPERI.IFIS, [2:0] PIPEPERI.IITV
0xA0070 USB0 16-bit
  [15] PIPE1CTR.BSTS, [14] PIPE1CTR.INBUFM, [10] PIPE1CTR.ATREPM, [9] PIPE1CTR.ACLRM, [8] PIPE1CTR.SQCLR, [7] PIPE1CTR.SQSET, [6] PIPE1CTR.SQMON, [5] PIPE1CTR.PBUSY, [1:0] PIPE1CTR.PID
0xA0072 USB0 16-bit
  [15] PIPE2CTR.BSTS, [14] PIPE2CTR.INBUFM, [10] PIPE2CTR.ATREPM, [9] PIPE2CTR.ACLRM, [8] PIPE2CTR.SQCLR, [7] PIPE2CTR.SQSET, [6] PIPE2CTR.SQMON, [5] PIPE2CTR.PBUSY, [1:0] PIPE2CTR.PID
0xA0074 USB0 16-bit
  [15] PIPE3CTR.BSTS, [14] PIPE3CTR.INBUFM, [10] PIPE3CTR.ATREPM, [9] PIPE3CTR.ACLRM, [8] PIPE3CTR.SQCLR, [7] PIPE3CTR.SQSET, [6] PIPE3CTR.SQMON, [5] PIPE3CTR.PBUSY, [1:0] PIPE3CTR.PID
0xA0076 USB0 16-bit
  [15] PIPE4CTR.BSTS, [14] PIPE4CTR.INBUFM, [10] PIPE4CTR.ATREPM, [9] PIPE4CTR.ACLRM, [8] PIPE4CTR.SQCLR, [7] PIPE4CTR.SQSET, [6] PIPE4CTR.SQMON, [5] PIPE4CTR.PBUSY, [1:0] PIPE4CTR.PID
0xA0078 USB0 16-bit
  [15] PIPE5CTR.BSTS, [14] PIPE5CTR.INBUFM, [10] PIPE5CTR.ATREPM, [9] PIPE5CTR.ACLRM, [8] PIPE5CTR.SQCLR, [7] PIPE5CTR.SQSET, [6] PIPE5CTR.SQMON, [5] PIPE5CTR.PBUSY, [1:0] PIPE5CTR.PID
0xA007A USB0 16-bit
  [15] PIPE6CTR.BSTS, [9] PIPE6CTR.ACLRM, [8] PIPE6CTR.SQCLR, [7] PIPE6CTR.SQSET, [6] PIPE6CTR.SQMON, [5] PIPE6CTR.PBUSY, [1:0] PIPE6CTR.PID
0xA007C USB0 16-bit
  [15] PIPE7CTR.BSTS, [9] PIPE7CTR.ACLRM, [8] PIPE7CTR.SQCLR, [7] PIPE7CTR.SQSET, [6] PIPE7CTR.SQMON, [5] PIPE7CTR.PBUSY, [1:0] PIPE7CTR.PID
0xA007E USB0 16-bit
  [15] PIPE8CTR.BSTS, [9] PIPE8CTR.ACLRM, [8] PIPE8CTR.SQCLR, [7] PIPE8CTR.SQSET, [6] PIPE8CTR.SQMON, [5] PIPE8CTR.PBUSY, [1:0] PIPE8CTR.PID
0xA0080 USB0 16-bit
  [15] PIPE9CTR.BSTS, [9] PIPE9CTR.ACLRM, [8] PIPE9CTR.SQCLR, [7] PIPE9CTR.SQSET, [6] PIPE9CTR.SQMON, [5] PIPE9CTR.PBUSY, [1:0] PIPE9CTR.PID
0xA0090 USB0 16-bit
  [9] PIPE1TRE.TRENB, [8] PIPE1TRE.TRCLR
0xA0094 USB0 16-bit
  [9] PIPE2TRE.TRENB, [8] PIPE2TRE.TRCLR
0xA0098 USB0 16-bit
  [9] PIPE3TRE.TRENB, [8] PIPE3TRE.TRCLR
0xA009C USB0 16-bit
  [9] PIPE4TRE.TRENB, [8] PIPE4TRE.TRCLR
0xA00A0 USB0 16-bit
  [9] PIPE5TRE.TRENB, [8] PIPE5TRE.TRCLR
0xA00D0 USB0 16-bit
  [7:6] DEVADD0.USBSPD
0xA00D2 USB0 16-bit
  [7:6] DEVADD1.USBSPD
0xA00D4 USB0 16-bit
  [7:6] DEVADD2.USBSPD
0xA00D6 USB0 16-bit
  [7:6] DEVADD3.USBSPD
0xA00D8 USB0 16-bit
  [7:6] DEVADD4.USBSPD
0xA00DA USB0 16-bit
  [7:6] DEVADD5.USBSPD
0xA0200 USB1 16-bit
  fields as USB0
0xA0204 USB1 16-bit
  [15:14] SYSSTS0.OVCMON, [6] SYSSTS0.HTACT, [2] SYSSTS0.IDMON, [1:0] SYSSTS0.LNST
0xA0208 USB1 16-bit
  [11] DVSTCTR0.HNPBTOA, [10] DVSTCTR0.EXICEN, [9] DVSTCTR0.VBUSEN, [8] DVSTCTR0.WKUP, [7] DVSTCTR0.RWUPE, [6] DVSTCTR0.USBRST, [5] DVSTCTR0.RESUME, [4] DVSTCTR0.UACT, [2:0] DVSTCTR0.RHST
0xA0214 USB1 16-bit
  [15:8] CFIFO.L, [7:0] CFIFO.H
0xA0218 USB1 16-bit
  [15:8] D0FIFO.L, [7:0] D0FIFO.H
0xA021C USB1 16-bit
  [15:8] D1FIFO.L, [7:0] D1FIFO.H
0xA0220 USB1 16-bit
  [15] CFIFOSEL.RCNT, [14] CFIFOSEL.REW, [10] CFIFOSEL.MBW, [8] CFIFOSEL.BIGEND, [5] CFIFOSEL.ISEL, [3:0] CFIFOSEL.CURPIPE
0xA0222 USB1 16-bit
  [15] CFIFOCTR.BVAL, [14] CFIFOCTR.BCLR, [13] CFIFOCTR.FRDY, [8:0] CFIFOCTR.DTLN
0xA0228 USB1 16-bit
  [15] D0FIFOSEL.RCNT, [14] D0FIFOSEL.REW, [13] D0FIFOSEL.DCLRM, [12] D0FIFOSEL.DREQE, [10] D0FIFOSEL.MBW, [8] D0FIFOSEL.BIGEND, [3:0] D0FIFOSEL.CURPIPE
0xA022A USB1 16-bit
  [15] D0FIFOCTR.BVAL, [14] D0FIFOCTR.BCLR, [13] D0FIFOCTR.FRDY, [8:0] D0FIFOCTR.DTLN
0xA022C USB1 16-bit
  [15] D1FIFOSEL.RCNT, [14] D1FIFOSEL.REW, [13] D1FIFOSEL.DCLRM, [12] D1FIFOSEL.DREQE, [10] D1FIFOSEL.MBW, [8] D1FIFOSEL.BIGEND, [3:0] D1FIFOSEL.CURPIPE
0xA022E USB1 16-bit
  [15] D1FIFOCTR.BVAL, [14] D1FIFOCTR.BCLR, [13] D1FIFOCTR.FRDY, [8:0] D1FIFOCTR.DTLN
0xA0230 USB1 16-bit
  [15] INTENB0.VBSE, [14] INTENB0.RSME, [13] INTENB0.SOFE, [12] INTENB0.DVSE, [11] INTENB0.CTRE, [10] INTENB0.BEMPE, [9] INTENB0.NRDYE, [8] INTENB0.BRDYE
0xA0232 USB1 16-bit
  [15] INTENB1.OVRCRE, [14] INTENB1.BCHGE, [12] INTENB1.DTCHE, [11] INTENB1.ATTCHE, [6] INTENB1.EOFERRE, [5] INTENB1.SIGNE, [4] INTENB1.SACKE
0xA0236 USB1 16-bit
  [n] BRDYENB.PIPE{n}BRDYE (n=0..9)
0xA0238 USB1 16-bit
  [n] NRDYENB.PIPE{n}NRDYE (n=0..9)
0xA023A USB1 16-bit
  [n] BEMPENB.PIPE{n}BEMPE (n=0..9)
0xA023C USB1 16-bit
  [8] SOFCFG.TRNENSEL, [6] SOFCFG.BRDYM, [4] SOFCFG.EDGESTS
0xA0240 USB1 16-bit
  [15] INTSTS0.VBINT, [14] INTSTS0.RESM, [13] INTSTS0.SOFR, [12] INTSTS0.DVST, [11] INTSTS0.CTRT, [10] INTSTS0.BEMP, [9] INTSTS0.NRDY, [8] INTSTS0.BRDY, [7] INTSTS0.VBSTS, [6:4] INTSTS0.DVSQ, [3] INTSTS0.VALID, [2:0] INTSTS0.CTSQ
0xA0242 USB1 16-bit
  [15] INTSTS1.OVRCR, [14] INTSTS1.BCHG, [12] INTSTS1.DTCH, [11] INTSTS1.ATTCH, [6] INTSTS1.EOFERR, [5] INTSTS1.SIGN, [4] INTSTS1.SACK
0xA0246 USB1 16-bit
  [n] BRDYSTS.PIPE{n}BRDY (n=0..9)
0xA0248 USB1 16-bit
  [n] NRDYSTS.PIPE{n}NRDY (n=0..9)
0xA024A USB1 16-bit
  [n] BEMPSTS.PIPE{n}BEMP (n=0..9)
0xA024C USB1 16-bit
  [15] FRMNUM.OVRN, [14] FRMNUM.CRCE, [10:0] FRMNUM.FRNM
0xA024E USB1 16-bit
  [15] DVCHGR.DVCHG
0xA0250 USB1 16-bit
  [11:8] USBADDR.STSRECOV, [6:0] USBADDR.USBADDR
0xA0254 USB1 16-bit
  [15:8] USBREQ.BREQUEST, [7:0] USBREQ.BMREQUESTTYPE
0xA025C USB1 16-bit
  [7] DCPCFG.SHTNAK, [4] DCPCFG.DIR
0xA025E USB1 16-bit
  [15:12] DCPMAXP.DEVSEL, [6:0] DCPMAXP.MXPS
0xA0260 USB1 16-bit
  [15] DCPCTR.BSTS, [14] DCPCTR.SUREQ, [11] DCPCTR.SUREQCLR, [8] DCPCTR.SQCLR, [7] DCPCTR.SQSET, [6] DCPCTR.SQMON, [5] DCPCTR.PBUSY, [2] DCPCTR.CCPL, [1:0] DCPCTR.PID
0xA0264 USB1 16-bit
  [3:0] PIPESEL.PIPESEL
0xA0268 USB1 16-bit
  [15:14] PIPECFG.TYPE, [10] PIPECFG.BFRE, [9] PIPECFG.DBLB, [7] PIPECFG.SHTNAK, [4] PIPECFG.DIR, [3:0] PIPECFG.EPNUM
0xA026C USB1 16-bit
  [15:12] PIPEMAXP.DEVSEL, [8:0] PIPEMAXP.MXPS
0xA026E USB1 16-bit
  [12] PIPEPERI.IFIS, [2:0] PIPEPERI.IITV
0xA0270 USB1 16-bit
  [15] PIPE1CTR.BSTS, [14] PIPE1CTR.INBUFM, [10] PIPE1CTR.ATREPM, [9] PIPE1CTR.ACLRM, [8] PIPE1CTR.SQCLR, [7] PIPE1CTR.SQSET, [6] PIPE1CTR.SQMON, [5] PIPE1CTR.PBUSY, [1:0] PIPE1CTR.PID
0xA0272 USB1 16-bit
  [15] PIPE2CTR.BSTS, [14] PIPE2CTR.INBUFM, [10] PIPE2CTR.ATREPM, [9] PIPE2CTR.ACLRM, [8] PIPE2CTR.SQCLR, [7] PIPE2CTR.SQSET, [6] PIPE2CTR.SQMON, [5] PIPE2CTR.PBUSY, [1:0] PIPE2CTR.PID
0xA0274 USB1 16-bit
  [15] PIPE3CTR.BSTS, [14] PIPE3CTR.INBUFM, [10] PIPE3CTR.ATREPM, [9] PIPE3CTR.ACLRM, [8] PIPE3CTR.SQCLR, [7] PIPE3CTR.SQSET, [6] PIPE3CTR.SQMON, [5] PIPE3CTR.PBUSY, [1:0] PIPE3CTR.PID
0xA0276 USB1 16-bit
  [15] PIPE4CTR.BSTS, [14] PIPE4CTR.INBUFM, [10] PIPE4CTR.ATREPM, [9] PIPE4CTR.ACLRM, [8] PIPE4CTR.SQCLR, [7] PIPE4CTR.SQSET, [6] PIPE4CTR.SQMON, [5] PIPE4CTR.PBUSY, [1:0] PIPE4CTR.PID
0xA0278 USB1 16-bit
  [15] PIPE5CTR.BSTS, [14] PIPE5CTR.INBUFM, [10] PIPE5CTR.ATREPM, [9] PIPE5CTR.ACLRM, [8] PIPE5CTR.SQCLR, [7] PIPE5CTR.SQSET, [6] PIPE5CTR.SQMON, [5] PIPE5CTR.PBUSY, [1:0] PIPE5CTR.PID
0xA027A USB1 16-bit
  [15] PIPE6CTR.BSTS, [9] PIPE6CTR.ACLRM, [8] PIPE6CTR.SQCLR, [7] PIPE6CTR.SQSET, [6] PIPE6CTR.SQMON, [5] PIPE6CTR.PBUSY, [1:0] PIPE6CTR.PID
0xA027C USB1 16-bit
  [15] PIPE7CTR.BSTS, [9] PIPE7CTR.ACLRM, [8] PIPE7CTR.SQCLR, [7] PIPE7CTR.SQSET, [6] PIPE7CTR.SQMON, [5] PIPE7CTR.PBUSY, [1:0] PIPE7CTR.PID
0xA027E USB1 16-bit
  [15] PIPE8CTR.BSTS, [9] PIPE8CTR.ACLRM, [8] PIPE8CTR.SQCLR, [7] PIPE8CTR.SQSET, [6] PIPE8CTR.SQMON, [5] PIPE8CTR.PBUSY, [1:0] PIPE8CTR.PID
0xA0280 USB1 16-bit
  [15] PIPE9CTR.BSTS, [9] PIPE9CTR.ACLRM, [8] PIPE9CTR.SQCLR, [7] PIPE9CTR.SQSET, [6] PIPE9CTR.SQMON, [5] PIPE9CTR.PBUSY, [1:0] PIPE9CTR.PID
0xA0290 USB1 16-bit
  [9] PIPE1TRE.TRENB, [8] PIPE1TRE.TRCLR
0xA0294 USB1 16-bit
  [9] PIPE2TRE.TRENB, [8] PIPE2TRE.TRCLR
0xA0298 USB1 16-bit
  [9] PIPE3TRE.TRENB, [8] PIPE3TRE.TRCLR
0xA029C USB1 16-bit
  [9] PIPE4TRE.TRENB, [8] PIPE4TRE.TRCLR
0xA02A0 USB1 16-bit
  [9] PIPE5TRE.TRENB, [8] PIPE5TRE.TRCLR
0xA02D0 USB1 16-bit
  [7:6] DEVADD0.USBSPD
0xA02D2 USB1 16-bit
  [7:6] DEVADD1.USBSPD
0xA02D4 USB1 16-bit
  [7:6] DEVADD2.USBSPD
0xA02D6 USB1 16-bit
  [7:6] DEVADD3.USBSPD
0xA02D8 USB1 16-bit
  [7:6] DEVADD4.USBSPD
0xA02DA USB1 16-bit
  [7:6] DEVADD5.USBSPD
0xA0400 USB 32-bit
  [31] DPUSR0R.DVBSTS1, [29] DPUSR0R.DOVCB1, [28] DPUSR0R.DOVCA1, [25] DPUSR0R.DM1, [24] DPUSR0R.DP1, [23] DPUSR0R.DVBSTS0, [21] DPUSR0R.DOVCB0, [20] DPUSR0R.DOVCA0, [17] DPUSR0R.DM0, [16] DPUSR0R.DP0, [12] DPUSR0R.FIXPHY1, [8] DPUSR0R.SRPC1, [4] DPUSR0R.FIXPHY0, [0] DPUSR0R.SRPC0
0xA0404 USB 32-bit
  [31] DPUSR1R.DVBINT1, [29] DPUSR1R.DOVRCRB1, [28] DPUSR1R.DOVRCRA1, [25] DPUSR1R.DMINT1, [24] DPUSR1R.DPINT1, [23] DPUSR1R.DVBINT0, [21] DPUSR1R.DOVRCRB0, [20] DPUSR1R.DOVRCRA0, [17] DPUSR1R.DMINT0, [16] DPUSR1R.DPINT0, [15] DPUSR1R.DVBSE1, [13] DPUSR1R.DOVRCRBE1, [12] DPUSR1R.DOVRCRAE1, [9] DPUSR1R.DMINTE1, [8] DPUSR1R.DPINTE1, [7] DPUSR1R.DVBSE0, [5] DPUSR1R.DOVRCRBE0, [4] DPUSR1R.DOVRCRAE0, [1] DPUSR1R.DMINTE0, [0] DPUSR1R.DPINTE0
0xC0000 EDMAC 32-bit
  [6] EDMR.DE, [5:4] EDMR.DL, [0] EDMR.SWR
0xC0008 EDMAC 32-bit
  [0] EDTRR.TR
0xC0010 EDMAC 32-bit
  [0] EDRRR.RR
0xC0028 EDMAC 32-bit
  [30] EESR.TWB, [26] EESR.TABT, [25] EESR.RABT, [24] EESR.RFCOF, [23] EESR.ADE, [22] EESR.ECI, [21] EESR.TC, [20] EESR.TDE, [19] EESR.TFUF, [18] EESR.FR, [17] EESR.RDE, [16] EESR.RFOF, [11] EESR.CND, [10] EESR.DLC, [9] EESR.CD, [8] EESR.TRO, [7] EESR.RMAF, [4] EESR.RRF, [3] EESR.RTLF, [2] EESR.RTSF, [1] EESR.PRE, [0] EESR.CERF
0xC0030 EDMAC 32-bit
  [30] EESIPR.TWBIP, [26] EESIPR.TABTIP, [25] EESIPR.RABTIP, [24] EESIPR.RFCOFIP, [23] EESIPR.ADEIP, [22] EESIPR.ECIIP, [21] EESIPR.TCIP, [20] EESIPR.TDEIP, [19] EESIPR.TFUFIP, [18] EESIPR.FRIP, [17] EESIPR.RDEIP, [16] EESIPR.RFOFIP, [11] EESIPR.CNDIP, [10] EESIPR.DLCIP, [9] EESIPR.CDIP, [8] EESIPR.TROIP, [7] EESIPR.RMAFIP, [4] EESIPR.RRFIP, [3] EESIPR.RTLFIP, [2] EESIPR.RTSFIP, [1] EESIPR.PREIP, [0] EESIPR.CERFIP
0xC0038 EDMAC 32-bit
  [11] TRSCER.CNDCE, [10] TRSCER.DLCCE, [9] TRSCER.CDCE, [8] TRSCER.TROCE, [7] TRSCER.RMAFCE, [4] TRSCER.RRFCE, [3] TRSCER.RTLFCE, [2] TRSCER.RTSFCE, [1] TRSCER.PRECE, [0] TRSCER.CERFCE
0xC0040 EDMAC 32-bit
  [15:0] RMFCR.MFC
0xC0048 EDMAC 32-bit
  [10:0] TFTR.TFT
0xC0050 EDMAC 32-bit
  [12:8] FDR.TFD, [4:0] FDR.RFD
0xC0058 EDMAC 32-bit
  [1] RMCR.RNC, [0] RMCR.RNR
0xC0064 EDMAC 32-bit
  [15:0] TFUCR.UNDER
0xC0068 EDMAC 32-bit
  [15:0] RFOCR.OVER
0xC006C EDMAC 32-bit
  [0] IOSR.ELB
0xC0070 EDMAC 32-bit
  [18:16] FCFTR.RFFO, [2:0] FCFTR.RFDO
0xC0078 EDMAC 32-bit
  [17:16] RPADIR.PADS, [5:0] RPADIR.PADR
0xC007C EDMAC 32-bit
  [4] TRIMD.TIM, [0] TRIMD.TIS
0xC0100 ETHERC 32-bit
  [20] ECMR.TPC, [19] ECMR.ZPE, [18] ECMR.PFR, [17] ECMR.RXF, [16] ECMR.TXF, [12] ECMR.PRCEF, [9] ECMR.MPDE, [6] ECMR.RE, [5] ECMR.TE, [3] ECMR.ILB, [2] ECMR.RTM, [1] ECMR.DM, [0] ECMR.PRM
0xC0108 ETHERC 32-bit
  [11:0] RFLR.RFL
0xC0110 ETHERC 32-bit
  [5] ECSR.BFR, [4] ECSR.PSRTO, [2] ECSR.LCHNG, [1] ECSR.MPD, [0] ECSR.ICD
0xC0118 ETHERC 32-bit
  [5] ECSIPR.BFSIPR, [4] ECSIPR.PSRTOIP, [2] ECSIPR.LCHNGIP, [1] ECSIPR.MPDIP, [0] ECSIPR.ICDIP
0xC0120 ETHERC 32-bit
  [3] PIR.MDI, [2] PIR.MDO, [1] PIR.MMD, [0] PIR.MDC
0xC0128 ETHERC 32-bit
  [0] PSR.LMON
0xC0140 ETHERC 32-bit
  [19:0] RDMLR.RMD
0xC0150 ETHERC 32-bit
  [4:0] IPGR.IPG
0xC0154 ETHERC 32-bit
  [15:0] APR.AP
0xC0158 ETHERC 32-bit
  [15:0] MPR.MP
0xC0160 ETHERC 32-bit
  [7:0] RFCF.RPAUSE
0xC0164 ETHERC 32-bit
  [15:0] TPAUSER.TPAUSE
0xC0168 ETHERC 32-bit
  [7:0] TPAUSECR.TXP
0xC016C ETHERC 32-bit
  [15:0] BCFRR.BCF
0xC01C8 ETHERC 32-bit
  [15:0] MALR.MA
0x7FC402 FLASH
  [4] FMODR.FRDMD
0x7FC410 FLASH
  [7] FASTAT.ROMAE, [4] FASTAT.CMDLK, [3] FASTAT.DFLAE, [1] FASTAT.DFLRPE, [0] FASTAT.DFLWPE
0x7FC411 FLASH
  [7] FAEINT.ROMAEIE, [4] FAEINT.CMDLKIE, [3] FAEINT.DFLAEIE, [1] FAEINT.DFLRPEIE, [0] FAEINT.DFLWPEIE
0x7FC412 FLASH
  [0] FRDYIE.FRDYIE
0x7FC440 FLASH 16-bit
  [15:8] DFLRE0.KEY, [n] DFLRE0.DBRE{n:02} (n=0..7)
0x7FC442 FLASH 16-bit
  [15:8] DFLRE1.KEY, [n-8] DFLRE1.DBRE{n:02} (n=8..15)
0x7FC450 FLASH 16-bit
  [15:8] DFLWE0.KEY, [n] DFLWE0.DBWE{n:02} (n=0..7)
0x7FC452 FLASH 16-bit
  [15:8] DFLWE1.KEY, [n-8] DFLWE1.DBWE{n:02} (n=8..15)
0x7FC454 FLASH 16-bit
  [15:8] FCURAME.KEY, [0] FCURAME.FCRME
0x7FFFB0 FLASH
  [7] FSTATR0.FRDY, [6] FSTATR0.ILGLERR, [5] FSTATR0.ERSERR, [4] FSTATR0.PRGERR, [3] FSTATR0.SUSRDY, [1] FSTATR0.ERSSPD, [0] FSTATR0.PRGSPD
0x7FFFB1 FLASH
  [7] FSTATR1.FCUERR, [4] FSTATR1.FLOCKST
0x7FFFB2 FLASH 16-bit
  [15:8] FENTRYR.FEKEY, [7] FENTRYR.FENTRYD, [0] FENTRYR.FENTRY0
0x7FFFB4 FLASH 16-bit
  [15:8] FPROTR.FPKEY, [0] FPROTR.FPROTCN
0x7FFFB6 FLASH 16-bit
  [15:8] FRESETR.FRKEY, [0] FRESETR.FRESET
0x7FFFBA FLASH 16-bit
  [15:8] FCMDR.CMDR, [7:0] FCMDR.PCMDR
0x7FFFC8 FLASH 16-bit
  [0] FCPSR.ESUSPMD
0x7FFFCA FLASH 16-bit
  [10:3] DFLBCCNT.BCADR, [0] DFLBCCNT.BCSIZE
0x7FFFCC FLASH 16-bit
  [7:0] FPESTAT.PEERRST
0x7FFFCE FLASH 16-bit
  [0] DFLBCSTAT.BCST
0x7FFFE8 FLASH 16-bit
  [7:0] PCKAR.PCKA
